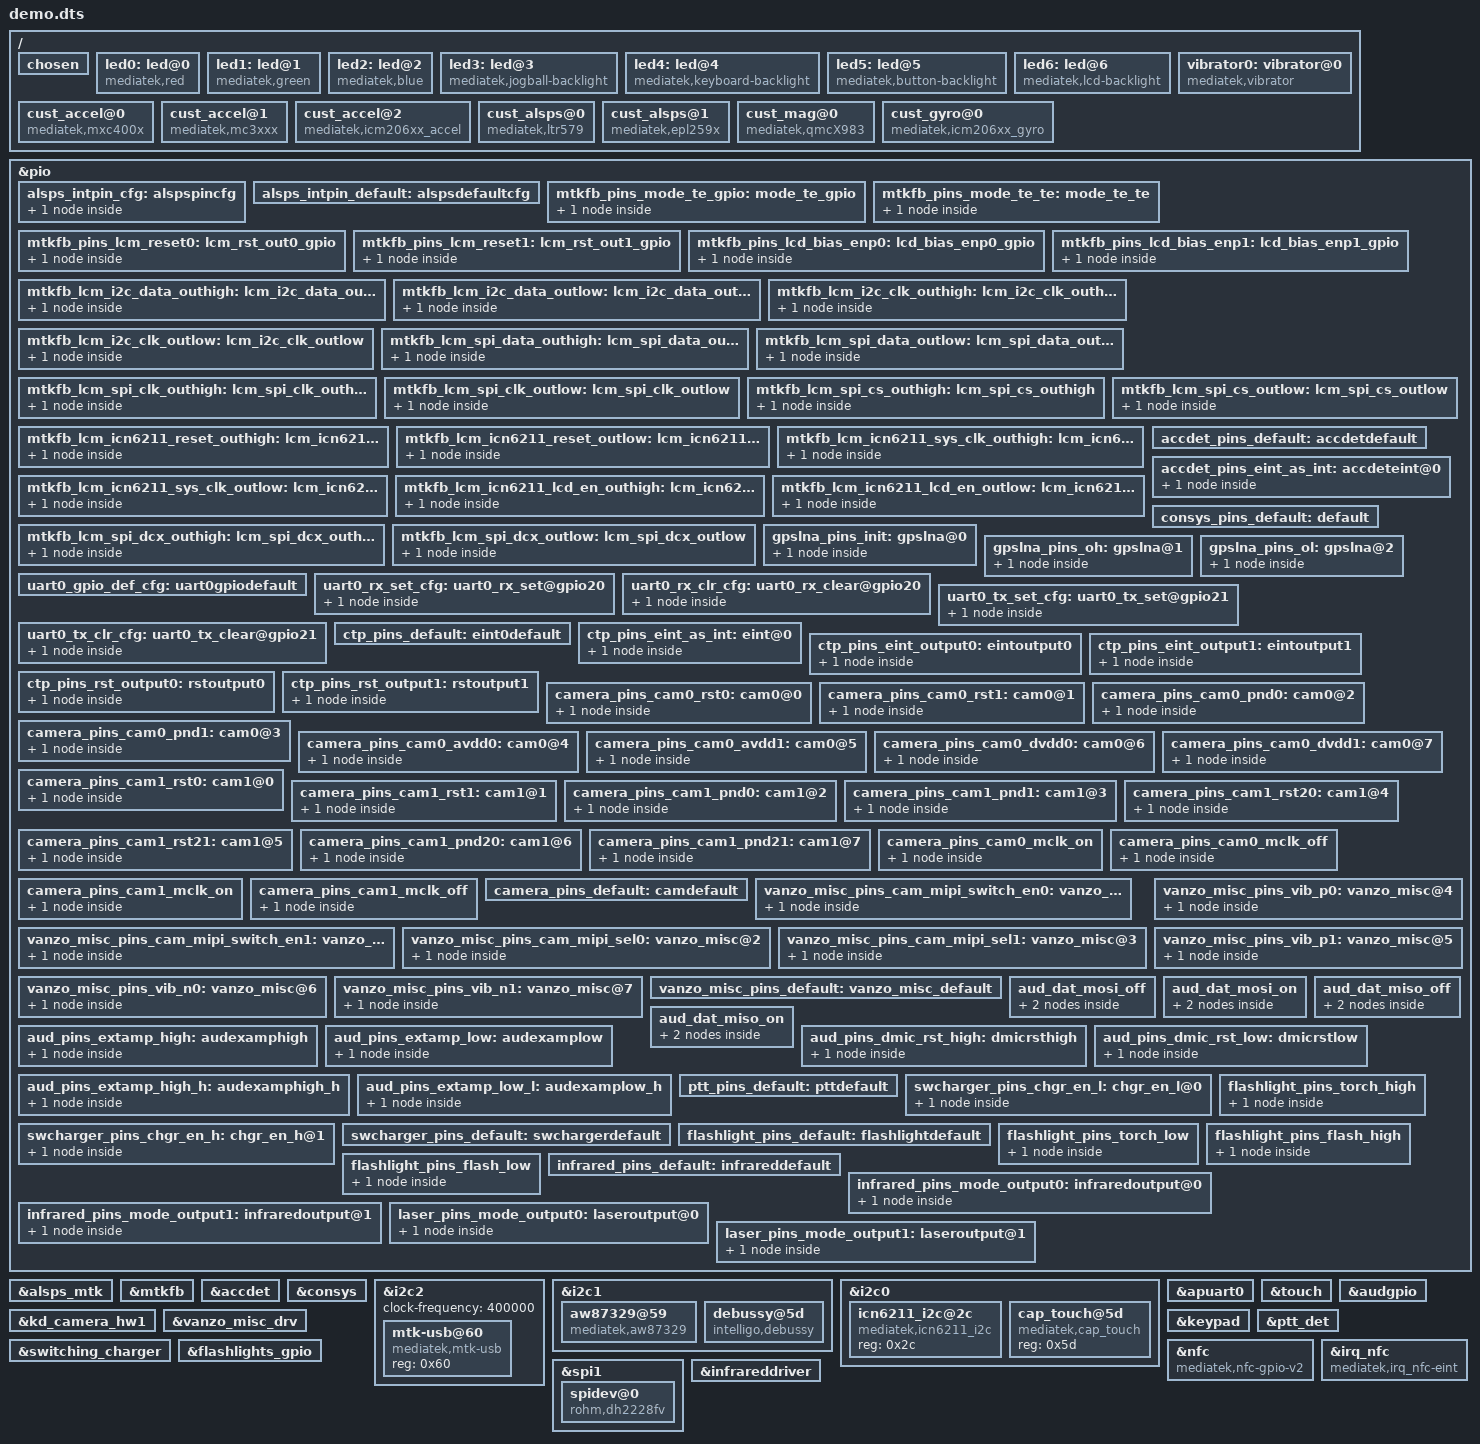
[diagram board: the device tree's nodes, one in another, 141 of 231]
/dts-v1/;
#include "mt6739.dtsi"
#include "cust.dtsi"

/ {
	chosen {
		bootargs = "console=tty0 console=ttyMT0,921600n1 root=/dev/ram initrd=0x44000000,\
0x1000000 loglevel=8 androidboot.selinux=permissive androidboot.hardware=mt6739 initcall_debug=1";
		/* fpga may has no lk, we need to specify display info here */
		/* fb buffer is reserved using this dts by memory node above */

		atag,videolfb-fb_base_l = <0x5e605000>;
		atag,videolfb-fb_base_h = <0>;
		atag,videolfb-islcmfound = <1>;
		atag,videolfb-islcm_inited = <0>;
		atag,videolfb-fps= <6000>;
		atag,videolfb-vramSize= <0x017bb000>;
		atag,videolfb-lcmname= "nt35521_hd_dsi_vdo_truly_nt50358_drv";
	};

	led0:led@0 {
		compatible = "mediatek,red";
		led_mode = <0>;
		data = <1>;
		pwm_config = <0 0 0 0 0>;
	};
	led1:led@1 {
		compatible = "mediatek,green";
		led_mode = <0>;
		data = <1>;
		pwm_config = <0 0 0 0 0>;
	};
	led2:led@2 {
		compatible = "mediatek,blue";
		led_mode = <0>;
		data = <1>;
		pwm_config = <0 0 0 0 0>;
	};
	led3:led@3 {
		compatible = "mediatek,jogball-backlight";
		led_mode = <0>;
		data = <1>;
		pwm_config = <0 0 0 0 0>;
	};
	led4:led@4 {
		compatible = "mediatek,keyboard-backlight";
		led_mode = <0>;
		data = <1>;
		pwm_config = <0 0 0 0 0>;
	};
	led5:led@5 {
		compatible = "mediatek,button-backlight";
		led_mode = <0>;
		data = <1>;
		pwm_config = <0 0 0 0 0>;
	};
	led6:led@6 {
		compatible = "mediatek,lcd-backlight";
		led_mode = <5>;
		data = <1>;
		pwm_config = <0 2 0 0 0>;
	};
	vibrator0:vibrator@0 {
		compatible = "mediatek,vibrator";
		vib_timer = <25>;
		vib_limit = <9>;
		vib_vol= <9>;
	};

/*  start sensor */
	cust_accel@0 {
		compatible = "mediatek,mxc400x";
		i2c_num	= <1>;
		i2c_addr = <0x15 0 0 0>;
		direction = <4>;
		power_id = <0xffff>;
		power_vol = <0>;
		firlen = <0>;
		is_batch_supported = <0>;
	};
	cust_accel@1 {
        compatible = "mediatek,mc3xxx";
        i2c_num = <1>;
        i2c_addr = <0x4c 0 0 0>;
        direction = <4>;
        power_id = <0xffff>;
        power_vol = <0>;
        firlen = <0>;
        is_batch_supported = <0>;
        };
	    cust_accel@2 {
        compatible = "mediatek,icm206xx_accel";
        i2c_num = <1>;
        i2c_addr = <0x68 0 0 0>;
        direction = <4>;
        power_id = <0xffff>;
        power_vol = <0>;
        firlen = <0>;
        is_batch_supported = <0>;
    };
	

	cust_alsps@0 {
        compatible = "mediatek,ltr579";
        i2c_num = <1>;
        i2c_addr = <0x53 0 0 0>;
        polling_mode_ps = <0>;
        polling_mode_als = <1>;
        power_id = <0xffff>;
        power_vol = <0>;
        als_level = <2 20 78 240 320 530 900 1200 1400 1700 2000 2500 3000 12694 35535>;
        als_value = <0 133 304 502 1004 2005 3058 5005 8008 10010 12000 16000 20000 20000 20000 20000>;
        ps_threshold_high = <200>;
        ps_threshold_low = <100>;
        is_batch_supported_ps = <0>;
        is_batch_supported_als = <0>;
    };
        cust_alsps@1 {
        compatible              = "mediatek,epl259x";
        i2c_num             = <2>;
        i2c_addr                = <0x49 0 0 0>;
        polling_mode_ps         = <0>;
        polling_mode_als        = <1>;
        power_id                = <0xffff>;
        power_vol               = <0>;
        als_level = <0 328 861 1377 3125 7721 7767 12621 23062 28430 33274 47116 57694 57694 65535>;
        als_value = <0 133 304 502 1004 2005 3058 5005 8008 10010 12000 16000 20000 20000 20000 20000>;
        ps_threshold_high       =  <34>;
        ps_threshold_low        =  <28>;
        is_batch_supported_ps   = <0>;
        is_batch_supported_als  = <0>;
        };
	
	cust_mag@0 {
        compatible              = "mediatek,qmcX983";
        i2c_num                 = <1>;
        i2c_addr                = <0x2c 0 0 0>;
        direction               = <7>;
        power_id                = <0xffff>;
        power_vol               = <0>;
        is_batch_supported      = <0>;
    };

    cust_gyro@0 {
        compatible          = "mediatek,icm206xx_gyro";
        i2c_num             = <1>;
        i2c_addr            = <0x69 0 0 0>;
        direction           = <4>;
        power_id            = <0xffff>;
        power_vol           = <0>;
        firlen              = <0>;
        is_batch_supported  = <0>;
    };
/* end sensor */
};

/* sensor gpio standization */
&pio {
	alsps_intpin_cfg: alspspincfg {

		pins_cmd_dat {
			pins = <PINMUX_GPIO1__FUNC_GPIO1>;
			slew-rate = <0>;
			bias-pull-up = <MTK_PUPD_SET_R1R0_01>;
		};
	};

	alsps_intpin_default: alspsdefaultcfg {

	};
};

&alsps_mtk {
	pinctrl-names = "pin_default", "pin_cfg";
	pinctrl-0 = <&alsps_intpin_default>;
	pinctrl-1 = <&alsps_intpin_cfg>;
	status = "okay";
};
/* sensor end */

/* DISPSYS GPIO standardization */
&pio {
	mtkfb_pins_mode_te_gpio: mode_te_gpio {
		pins_cmd_dat {
			pins = <PINMUX_GPIO84__FUNC_DSI_TE>;
		};
	};

	mtkfb_pins_mode_te_te: mode_te_te {
		pins_cmd_dat {
			pins = <PINMUX_GPIO84__FUNC_DSI_TE>;
		};
	};

	mtkfb_pins_lcm_reset0: lcm_rst_out0_gpio {
		pins_cmd_dat {
			pins = <PINMUX_GPIO83__FUNC_GPIO83>;
			slew-rate = <1>;
			output-low;
		};
	};

	mtkfb_pins_lcm_reset1: lcm_rst_out1_gpio {
		pins_cmd_dat {
			pins = <PINMUX_GPIO83__FUNC_GPIO83>;
			slew-rate = <1>;
			output-high;
		};
	};

	mtkfb_pins_lcd_bias_enp0: lcd_bias_enp0_gpio {
		pins_cmd_dat {
			pins = <PINMUX_GPIO26__FUNC_GPIO26>;
			slew-rate = <1>;
			output-low;
		};
	};
	mtkfb_pins_lcd_bias_enp1: lcd_bias_enp1_gpio {
		pins_cmd_dat {
			pins = <PINMUX_GPIO26__FUNC_GPIO26>;
			slew-rate = <1>;
			output-high;
		};
	};
	mtkfb_lcm_i2c_data_outhigh: lcm_i2c_data_outhigh {
		pins_cmd_dat {
			pins = <PINMUX_GPIO128__FUNC_GPIO128>;
			slew-rate = <1>;
			output-high;
		};
	};
	mtkfb_lcm_i2c_data_outlow: lcm_i2c_data_outlow {
		pins_cmd_dat {
			pins = <PINMUX_GPIO128__FUNC_GPIO128>;
			slew-rate = <1>;
			output-low;
		};
	};
	mtkfb_lcm_i2c_clk_outhigh: lcm_i2c_clk_outhigh {
		pins_cmd_dat {
			pins = <PINMUX_GPIO129__FUNC_GPIO129>;
			slew-rate = <1>;
			output-high;
		};
	};
	mtkfb_lcm_i2c_clk_outlow: lcm_i2c_clk_outlow {
		pins_cmd_dat {
			pins = <PINMUX_GPIO129__FUNC_GPIO129>;
			slew-rate = <1>;
			output-low;
		};
	};
	mtkfb_lcm_spi_data_outhigh: lcm_spi_data_outhigh {
		pins_cmd_dat {
			pins = <PINMUX_GPIO29__FUNC_GPIO29>;
			slew-rate = <1>;
			output-high;
		};
	};
	mtkfb_lcm_spi_data_outlow: lcm_spi_data_outlow {
		pins_cmd_dat {
			pins = <PINMUX_GPIO29__FUNC_GPIO29>;
			slew-rate = <1>;
			output-low;
		};
	};
	mtkfb_lcm_spi_clk_outhigh: lcm_spi_clk_outhigh {
		pins_cmd_dat {
			pins = <PINMUX_GPIO28__FUNC_GPIO28>;
			slew-rate = <1>;
			output-high;
		};
	};
	mtkfb_lcm_spi_clk_outlow: lcm_spi_clk_outlow {
		pins_cmd_dat {
			pins = <PINMUX_GPIO28__FUNC_GPIO28>;
			slew-rate = <1>;
			output-low;
		};
	};
	mtkfb_lcm_spi_cs_outhigh: lcm_spi_cs_outhigh {
		pins_cmd_dat {
			pins = <PINMUX_GPIO30__FUNC_GPIO30>;
			slew-rate = <1>;
			output-high;
		};
	};
	mtkfb_lcm_spi_cs_outlow: lcm_spi_cs_outlow {
		pins_cmd_dat {
			pins = <PINMUX_GPIO30__FUNC_GPIO30>;
			slew-rate = <1>;
			output-low;
		};
	};

	mtkfb_lcm_icn6211_reset_outhigh: lcm_icn6211_reset_outhigh {
		pins_cmd_dat {
			pins = <PINMUX_GPIO108__FUNC_GPIO108>;
			slew-rate = <1>;
			output-high;
		};
	};
	mtkfb_lcm_icn6211_reset_outlow: lcm_icn6211_reset_outlow {
		pins_cmd_dat {
			pins = <PINMUX_GPIO108__FUNC_GPIO108>;
			slew-rate = <1>;
			output-low;
		};
	};

	mtkfb_lcm_icn6211_sys_clk_outhigh: lcm_icn6211_sys_clk_outhigh {
		pins_cmd_dat {
			pins = <PINMUX_GPIO86__FUNC_GPIO86>;
			slew-rate = <1>;
			output-high;
		};
	};
	mtkfb_lcm_icn6211_sys_clk_outlow: lcm_icn6211_sys_clk_outlow {
		pins_cmd_dat {
			pins = <PINMUX_GPIO86__FUNC_GPIO86>;
			slew-rate = <1>;
			output-low;
		};
	};

	mtkfb_lcm_icn6211_lcd_en_outhigh: lcm_icn6211_lcd_en_outhigh {
		pins_cmd_dat {
			pins = <PINMUX_GPIO109__FUNC_GPIO109>;
			slew-rate = <1>;
			output-high;
		};
	};
	mtkfb_lcm_icn6211_lcd_en_outlow: lcm_icn6211_lcd_en_outlow {
		pins_cmd_dat {
			pins = <PINMUX_GPIO109__FUNC_GPIO109>;
			slew-rate = <1>;
			output-low;
		};
	};
       mtkfb_lcm_spi_dcx_outhigh: lcm_spi_dcx_outhigh {
                               pins_cmd_dat {
                                   pins = <PINMUX_GPIO26__FUNC_GPIO26>;
                                   slew-rate = <1>;
                                   output-high;
                               };
                           };
       mtkfb_lcm_spi_dcx_outlow: lcm_spi_dcx_outlow {
                              pins_cmd_dat {
                                  pins = <PINMUX_GPIO26__FUNC_GPIO26>;
                                  slew-rate = <1>;
                                  output-low;
                              };
                          };

};

&mtkfb {
	pinctrl-names = "mode_te_gpio", "mode_te_te", "lcm_rst_out0_gpio",
		"lcm_rst_out1_gpio", "lcd_bias_enp0_gpio", "lcd_bias_enp1_gpio",
		"lcm_i2c_data_outhigh", "lcm_i2c_data_outlow", "lcm_i2c_clk_outhigh","lcm_i2c_clk_outlow",
		"lcm_spi_data_outhigh", "lcm_spi_data_outlow", "lcm_spi_clk_outhigh","lcm_spi_clk_outlow","lcm_spi_cs_outhigh","lcm_spi_cs_outlow",
		"lcm_icn6211_reset_outhigh","lcm_icn6211_reset_outlow","lcm_icn6211_sys_clk_outhigh","lcm_icn6211_sys_clk_outlow","lcm_icn6211_lcd_en_outhigh","lcm_icn6211_lcd_en_outlow","lcm_spi_dcx_outhigh","lcm_spi_dcx_outlow";
	pinctrl-0 = <&mtkfb_pins_mode_te_gpio>;
	pinctrl-1 = <&mtkfb_pins_mode_te_te>;
	pinctrl-2 = <&mtkfb_pins_lcm_reset0>;
	pinctrl-3 = <&mtkfb_pins_lcm_reset1>;
	pinctrl-4 = <&mtkfb_pins_lcd_bias_enp0>;
	pinctrl-5 = <&mtkfb_pins_lcd_bias_enp1>;
	pinctrl-6 = <&mtkfb_lcm_i2c_data_outhigh>;
	pinctrl-7 = <&mtkfb_lcm_i2c_data_outlow>;
	pinctrl-8 = <&mtkfb_lcm_i2c_clk_outhigh>;
	pinctrl-9 = <&mtkfb_lcm_i2c_clk_outlow>;
	pinctrl-10 = <&mtkfb_lcm_spi_data_outhigh>;
	pinctrl-11 = <&mtkfb_lcm_spi_data_outlow>;
	pinctrl-12 = <&mtkfb_lcm_spi_clk_outhigh>;
	pinctrl-13 = <&mtkfb_lcm_spi_clk_outlow>;
	pinctrl-14 = <&mtkfb_lcm_spi_cs_outhigh>;
	pinctrl-15 = <&mtkfb_lcm_spi_cs_outlow>;
	pinctrl-16 = <&mtkfb_lcm_icn6211_reset_outhigh>;
	pinctrl-17 = <&mtkfb_lcm_icn6211_reset_outlow>;
	pinctrl-18 = <&mtkfb_lcm_icn6211_sys_clk_outhigh>;
	pinctrl-19 = <&mtkfb_lcm_icn6211_sys_clk_outlow>;
	pinctrl-20 = <&mtkfb_lcm_icn6211_lcd_en_outhigh>;
	pinctrl-21 = <&mtkfb_lcm_icn6211_lcd_en_outlow>;
        pinctrl-22 = <&mtkfb_lcm_spi_dcx_outhigh>;
        pinctrl-23 = <&mtkfb_lcm_spi_dcx_outlow>;
	status = "okay";
};
/* DISPSYS GPIO standardization end */


/* accdet start */
&accdet {
	/* accdet micbias voltage: 0x07,2.7v;0x05,2.5v;0x02,1.9v */
	accdet-mic-vol = <6>;
	headset-mode-setting = <0x500 0x500 1 0x1f0 0x800 0x800 0x20 0x44>;
	accdet-plugout-debounce = <1>;
	/*1:ACC mode, 2:low cost without in bias, 6:low cost with in bias*/
	accdet-mic-mode = <1>;
	/* eint_level_trigger: 8,LEVEL_LOW(default);4,LEVEL_HIGH;others,LEVEL_LOW */
	headset-eint-level-pol = <8>;
	/*0--MD_MAX--UP_MAX--DW_MAX*/
	headset-three-key-threshold = <0 80 220 400>;
	headset-three-key-threshold-CDD = <0 121 192 600>;
	/*0--MD_MAX--VOICE_MAX--UP_MAX--DW_MAX*/
	headset-four-key-threshold = <0 58 121 192 400>;
	/* ACCDET GPIO standardization ACC mode no use */
	pinctrl-names = "default", "state_eint_as_int";
	pinctrl-0 = <&accdet_pins_default>;
	pinctrl-1 = <&accdet_pins_eint_as_int>;
	status = "okay";
};
&pio {
	accdet_pins_default: accdetdefault {
	};
	accdet_pins_eint_as_int: accdeteint@0 {
		pins_cmd_dat {
			/*pins = <PINMUX_GPIO51__FUNC_GPIO51>;*/
			slew-rate = <0>;
			bias-disable;
		};
	};
};
/* accdet end */

/* CONSYS GPIO standardization */
&pio {
	consys_pins_default: default {
	};
	gpslna_pins_init: gpslna@0 {
		pins_cmd_dat {
			pins = <PINMUX_GPIO125__FUNC_GPIO125>;
			slew-rate = <0>;
			bias-disable;
			output-low;
		};
	};
	gpslna_pins_oh: gpslna@1 {
		pins_cmd_dat {
			pins = <PINMUX_GPIO125__FUNC_GPIO125>;
			slew-rate = <1>;
			output-high;
		};
	};
	gpslna_pins_ol: gpslna@2 {
		pins_cmd_dat {
			pins = <PINMUX_GPIO125__FUNC_GPIO125>;
			slew-rate = <1>;
			output-low;
		};
	};
};
&consys {
	pinctrl-names = "default", "gps_lna_state_init", "gps_lna_state_oh", "gps_lna_state_ol";
	pinctrl-0 = <&consys_pins_default>;
	pinctrl-1 = <&gpslna_pins_init>;
	pinctrl-2 = <&gpslna_pins_oh>;
	pinctrl-3 = <&gpslna_pins_ol>;
	status = "okay";
};

&i2c2 {
	#address-cells = <1>;
	#size-cells = <0>;
	clock-frequency = <400000>;

	mtk-usb@60 {
		compatible = "mediatek,mtk-usb";
		reg = <0x60>;
		status = "okay";
	};
};

&i2c1 {
#address-cells = <1>;
#size-cells = <0>;
    clock-frequency = <400000>;
    mediatek,use-open-drain;

    aw87329@59 {
        compatible = "mediatek,aw87329";
        reg = <0x59>;
        reset-gpio = <&pio 123 0>;
        status = "okay";
    };

    debussy@5d{
        status = "okay";
        compatible = "intelligo,debussy";
        reg = <0x5d>;
        ig,reset-gpio = <&pio 15 0>;
        ig,reset-hold-time = <5>;
        ig,reset-release-time = <150>;
        ig,enable-kws = <1>;
        ig,debounce = <2>;
        ig,device_name = "debussy.5d";
        ig,max_data_length_i2c = <256>;
        ig,enable-spi = <0>;
    };
};


&i2c0 {
#address-cells = <1>;
#size-cells = <0>;
    clock-frequency = <400000>;
    mediatek,use-open-drain;
    icn6211_i2c@2c {
        compatible = "mediatek,icn6211_i2c";
        reg = <0x2c>;
        status = "okay";
    };

    cap_touch@5d {
        compatible = "mediatek,cap_touch";
        reg = <0x5d>;
        status = "okay";
    };

};

/* UART GPIO */
&apuart0 {
	pinctrl-names = "uart0_gpio_default",
			"uart0_rx_set",
			"uart0_rx_clear",
			"uart0_tx_set",
			"uart0_tx_clear";
	pinctrl-0 = <&uart0_gpio_def_cfg>;
	pinctrl-1 = <&uart0_rx_set_cfg>;
	pinctrl-2 = <&uart0_rx_clr_cfg>;
	pinctrl-3 = <&uart0_tx_set_cfg>;
	pinctrl-4 = <&uart0_tx_clr_cfg>;
	status = "okay";
};

&pio {
	/* UART GPIO Settings - Start */
	/* UART0: rx set, rx clear, tx clear, tx clear*/
	uart0_gpio_def_cfg:uart0gpiodefault {

	};
	uart0_rx_set_cfg:uart0_rx_set@gpio20 {
		pins_cmd_dat {
			pins = <PINMUX_GPIO20__FUNC_UART0RX>;
		};
	};
	uart0_rx_clr_cfg:uart0_rx_clear@gpio20 {
		pins_cmd_dat {
			pins = <PINMUX_GPIO20__FUNC_GPIO20>;
			slew-rate = <1>;
			output-high;
		};
	};
	uart0_tx_set_cfg:uart0_tx_set@gpio21 {
		pins_cmd_dat {
			pins = <PINMUX_GPIO21__FUNC_UART0TX>;
		};
	};
	uart0_tx_clr_cfg:uart0_tx_clear@gpio21 {
		pins_cmd_dat {
			pins = <PINMUX_GPIO21__FUNC_GPIO21>;
			slew-rate = <1>;
			output-high;
		};
	};
};/* UART GPIO end */

/* TOUCH start */
&touch {
	tpd-resolution = <720 1280>;
	use-tpd-button = <0>;
	tpd-key-num = <3>;
	tpd-key-local= <139 172 158 0>;
	tpd-key-dim-local = <90 883 100 40 230 883 100 40 370 883 100 40 0 0 0 0>;
	tpd-max-touch-num = <5>;
	tpd-filter-enable = <1>;
	tpd-filter-pixel-density = <106>;
	tpd-filter-custom-prameters = <0 0 0 0 0 0 0 0 0 0 0 0>;
	tpd-filter-custom-speed = <0 0 0>;
	pinctrl-names = "default", "state_eint_as_int", "state_eint_output0", "state_eint_output1",
		"state_rst_output0", "state_rst_output1";
	pinctrl-0 = <&ctp_pins_default>;
	pinctrl-1 = <&ctp_pins_eint_as_int>;
	pinctrl-2 = <&ctp_pins_eint_output0>;
	pinctrl-3 = <&ctp_pins_eint_output1>;
	pinctrl-4 = <&ctp_pins_rst_output0>;
	pinctrl-5 = <&ctp_pins_rst_output1>;
	status = "okay";
};
&pio {
	ctp_pins_default: eint0default {
	};
	ctp_pins_eint_as_int: eint@0 {
		pins_cmd_dat {
			pins = <PINMUX_GPIO6__FUNC_GPIO6>;
			slew-rate = <0>;
			bias-disable;
		};
	};
	ctp_pins_eint_output0: eintoutput0 {
		pins_cmd_dat {
			pins = <PINMUX_GPIO6__FUNC_GPIO6>;
			slew-rate = <1>;
			output-low;
		};
	};
	ctp_pins_eint_output1: eintoutput1 {
		pins_cmd_dat {
			pins = <PINMUX_GPIO6__FUNC_GPIO6>;
			slew-rate = <1>;
			output-high;
		};
	};
	ctp_pins_rst_output0: rstoutput0 {
		pins_cmd_dat {
			pins = <PINMUX_GPIO124__FUNC_GPIO124>;
			slew-rate = <1>;
			output-low;
		};
	};
	ctp_pins_rst_output1: rstoutput1 {
		pins_cmd_dat {
			pins = <PINMUX_GPIO124__FUNC_GPIO124>;
			slew-rate = <1>;
			output-high;
		};
	};
};
/* TOUCH end */

/* CAMERA GPIO standardization */
&pio {
camera_pins_cam0_rst0: cam0@0 {
                           pins_cmd_dat {
                               pins = <PINMUX_GPIO33__FUNC_GPIO33>;
                               slew-rate = <1>; /*direction 0:in, 1:out*/
                               output-low;/*direction out used only. output_low or high*/
                           };
                       };
camera_pins_cam0_rst1: cam0@1 {
                           pins_cmd_dat {
                               pins = <PINMUX_GPIO33__FUNC_GPIO33>;
                               slew-rate = <1>;
                               output-high;
                           };
                       };
camera_pins_cam0_pnd0: cam0@2 {
                           pins_cmd_dat {
                               pins = <PINMUX_GPIO34__FUNC_GPIO34>;
                               slew-rate = <1>;
                               output-low;
                           };
                       };
camera_pins_cam0_pnd1: cam0@3 {
                           pins_cmd_dat {
                               pins = <PINMUX_GPIO34__FUNC_GPIO34>;
                               slew-rate = <1>;
                               output-high;
                           };
                       };
camera_pins_cam0_avdd0: cam0@4 {
                           pins_cmd_dat {
                               pins = <PINMUX_GPIO36__FUNC_GPIO36>;
                               slew-rate = <1>;
                               output-low;
                           };
                       };
camera_pins_cam0_avdd1: cam0@5 {
                           pins_cmd_dat {
                               pins = <PINMUX_GPIO36__FUNC_GPIO36>;
                               slew-rate = <1>;
                               output-high;
                           };
                       };
camera_pins_cam0_dvdd0: cam0@6 {
                           pins_cmd_dat {
                               pins = <PINMUX_GPIO9__FUNC_GPIO9>;
                               slew-rate = <1>;
                               output-low;
                           };
                       };
camera_pins_cam0_dvdd1: cam0@7 {
                           pins_cmd_dat {
                               pins = <PINMUX_GPIO9__FUNC_GPIO9>;
                               slew-rate = <1>;
                               output-high;
                           };
                       };
camera_pins_cam1_rst0: cam1@0 {
                           pins_cmd_dat {
                               pins = <PINMUX_GPIO22__FUNC_GPIO22>;
                               slew-rate = <1>; /*direction 0:in, 1:out*/
                               output-low;/*direction out used only. output_low or high*/
                           };
                       };
camera_pins_cam1_rst1: cam1@1 {
                           pins_cmd_dat {
                               pins = <PINMUX_GPIO22__FUNC_GPIO22>;
                               slew-rate = <1>;
                               output-high;
                           };
                       };
camera_pins_cam1_pnd0: cam1@2 {
                           pins_cmd_dat {
                               pins = <PINMUX_GPIO23__FUNC_GPIO23>;
                               slew-rate = <1>;
                               output-low;
                           };
                       };
camera_pins_cam1_pnd1: cam1@3 {
                           pins_cmd_dat {
                               pins = <PINMUX_GPIO23__FUNC_GPIO23>;
                               slew-rate = <1>;
                               output-high;
                           };
                       };
camera_pins_cam1_rst20: cam1@4 {
                           pins_cmd_dat {
                               pins = <PINMUX_GPIO32__FUNC_GPIO32>;
                               slew-rate = <1>; /*direction 0:in, 1:out*/
                               output-low;/*direction out used only. output_low or high*/
                           };
                       };
camera_pins_cam1_rst21: cam1@5 {
                           pins_cmd_dat {
                               pins = <PINMUX_GPIO32__FUNC_GPIO32>;
                               slew-rate = <1>;
                               output-high;
                           };
                       };
camera_pins_cam1_pnd20: cam1@6 {
                           pins_cmd_dat {
                               pins = <PINMUX_GPIO31__FUNC_GPIO31>;
                               slew-rate = <1>;
                               output-low;
                           };
                       };
camera_pins_cam1_pnd21: cam1@7 {
                           pins_cmd_dat {
                               pins = <PINMUX_GPIO31__FUNC_GPIO31>;
                               slew-rate = <1>;
                               output-high;
                           };
                       };
camera_pins_cam0_mclk_on: camera_pins_cam0_mclk_on {
                              pins_cmd_dat {
                                  pins = <PINMUX_GPIO126__FUNC_CMMCLK0>;
                              };
                          };
camera_pins_cam0_mclk_off: camera_pins_cam0_mclk_off {
                               pins_cmd_dat {
                                   pins = <PINMUX_GPIO126__FUNC_GPIO126>;
                               };
                           };
camera_pins_cam1_mclk_on: camera_pins_cam1_mclk_on {
                              pins_cmd_dat {
                                  pins = <PINMUX_GPIO126__FUNC_CMMCLK0>;
                              };
                          };
camera_pins_cam1_mclk_off: camera_pins_cam1_mclk_off {
                               pins_cmd_dat {
                                   pins = <PINMUX_GPIO126__FUNC_GPIO126>;
                               };
                           };
camera_pins_default: camdefault {
                     };

};

&kd_camera_hw1 {
    pinctrl-names = "default",
        "cam0_rst0", "cam0_rst1", "cam0_pnd0", "cam0_pnd1","cam_ldo_vcama_0","cam_ldo_vcama_1",
        "cam1_rst0", "cam1_rst1", "cam1_pnd0", "cam1_pnd1",
        "cam0_mclk_on", "cam0_mclk_off",
        "cam1_mclk_on", "cam1_mclk_off",
        "cam1_rst20","cam1_rst21","cam1_pnd20","cam1_pnd21","cam_ldo_vcamd_1","cam_ldo_vcamd_0";

    pinctrl-0 = <&camera_pins_default>;
    pinctrl-1 = <&camera_pins_cam0_rst0>;
    pinctrl-2 = <&camera_pins_cam0_rst1>;
    pinctrl-3 = <&camera_pins_cam0_pnd0>;
    pinctrl-4 = <&camera_pins_cam0_pnd1>;
    pinctrl-5 = <&camera_pins_cam0_avdd0>;
    pinctrl-6 = <&camera_pins_cam0_avdd1>;
    pinctrl-7 = <&camera_pins_cam1_rst0>;
    pinctrl-8 = <&camera_pins_cam1_rst1>;
    pinctrl-9 = <&camera_pins_cam1_pnd0>;
    pinctrl-10 = <&camera_pins_cam1_pnd1>;
    pinctrl-11 = <&camera_pins_cam0_mclk_on>;
    pinctrl-12 = <&camera_pins_cam0_mclk_off>;
    pinctrl-13 = <&camera_pins_cam1_mclk_on>;
    pinctrl-14 = <&camera_pins_cam1_mclk_off>;
    pinctrl-15 = <&camera_pins_cam1_rst20>;
    pinctrl-16 = <&camera_pins_cam1_rst21>;
    pinctrl-17 = <&camera_pins_cam1_pnd20>;
    pinctrl-18 = <&camera_pins_cam1_pnd21>;
    pinctrl-19 = <&camera_pins_cam0_dvdd1>;
    pinctrl-20 = <&camera_pins_cam0_dvdd0>;
    status = "okay";

};

/* CAMERA GPIO end */

&pio {
vanzo_misc_pins_cam_mipi_switch_en0: vanzo_misc@0 {
                           pins_cmd_dat {
                               pins = <PINMUX_GPIO53__FUNC_GPIO53>;
                               slew-rate = <1>;
                               output-low;
                           };
                       };
vanzo_misc_pins_cam_mipi_switch_en1: vanzo_misc@1 {
                           pins_cmd_dat {
                               pins = <PINMUX_GPIO53__FUNC_GPIO53>;
                               slew-rate = <1>;
                               output-high;
                           };
                       };
vanzo_misc_pins_cam_mipi_sel0: vanzo_misc@2 {
                           pins_cmd_dat {
                               pins = <PINMUX_GPIO54__FUNC_GPIO54>;
                               slew-rate = <1>;
                               output-low;
                           };
                       };
vanzo_misc_pins_cam_mipi_sel1: vanzo_misc@3 {
                           pins_cmd_dat {
                               pins = <PINMUX_GPIO54__FUNC_GPIO54>;
                               slew-rate = <1>;
                               output-high;
                           };
                       };
vanzo_misc_pins_vib_p0: vanzo_misc@4 {
                           pins_cmd_dat {
                               pins = <PINMUX_GPIO2__FUNC_GPIO2>;
                               slew-rate = <1>;
                               output-low;
                           };
                       };
vanzo_misc_pins_vib_p1: vanzo_misc@5 {
                           pins_cmd_dat {
                               pins = <PINMUX_GPIO2__FUNC_GPIO2>;
                               slew-rate = <1>;
                               output-high;
                           };
                       };
vanzo_misc_pins_vib_n0: vanzo_misc@6 {
                           pins_cmd_dat {
                               pins = <PINMUX_GPIO3__FUNC_GPIO3>;
                               slew-rate = <1>;
                               output-low;
                           };
                       };
vanzo_misc_pins_vib_n1: vanzo_misc@7 {
                           pins_cmd_dat {
                               pins = <PINMUX_GPIO3__FUNC_GPIO3>;
                               slew-rate = <1>;
                               output-high;
                           };
                       };
vanzo_misc_pins_default: vanzo_misc_default {
                         };
};
&vanzo_misc_drv {
    pinctrl-names = "default","cam_mipi_switch_en_1","cam_mipi_switch_en_0","cam_mipi_switch_sel_1","cam_mipi_switch_sel_0","vib_p1","vib_p0","vib_n1","vib_n0";
    pinctrl-0 = <&vanzo_misc_pins_default>;
    pinctrl-1 = <&vanzo_misc_pins_cam_mipi_switch_en1>;
    pinctrl-2 = <&vanzo_misc_pins_cam_mipi_switch_en0>;
    pinctrl-3 = <&vanzo_misc_pins_cam_mipi_sel1>;
    pinctrl-4 = <&vanzo_misc_pins_cam_mipi_sel0>;
    pinctrl-5 = <&vanzo_misc_pins_vib_p1>;
    pinctrl-6 = <&vanzo_misc_pins_vib_p0>;
    pinctrl-7 = <&vanzo_misc_pins_vib_n1>;
    pinctrl-8 = <&vanzo_misc_pins_vib_n0>;
};
/* AUDIO GPIO standardization */
&audgpio {
	pinctrl-names = "aud_dat_mosi_off",
			"aud_dat_mosi_on",
			"aud_dat_miso_off",
			"aud_dat_miso_on",
			"extamp-pullhigh",
			"extamp-pulllow",
			"dmic_rst_high",
			"dmic_rst_low";
	pinctrl-0 = <&aud_dat_mosi_off>;
	pinctrl-1 = <&aud_dat_mosi_on>;
	pinctrl-2 = <&aud_dat_miso_off>;
	pinctrl-3 = <&aud_dat_miso_on>;
	pinctrl-4 = <&aud_pins_extamp_high>;
	pinctrl-5 = <&aud_pins_extamp_low>;
	pinctrl-6 = <&aud_pins_dmic_rst_high>;
	pinctrl-7 = <&aud_pins_dmic_rst_low>;
	status = "okay";
};

&pio {
	aud_dat_mosi_off: aud_dat_mosi_off {
		pins_cmd1_dat {
			pins = <PINMUX_GPIO63__FUNC_GPIO63>;
			input-enable;
			slew-rate = <0>;
			bias-disable;
		};
		pins_cmd2_dat {
			pins = <PINMUX_GPIO64__FUNC_GPIO64>;
			input-enable;
			slew-rate = <0>;
			bias-disable;
		};
	};

	aud_dat_mosi_on: aud_dat_mosi_on {
		pins_cmd1_dat {
			pins = <PINMUX_GPIO63__FUNC_AUD_DAT_MOSI0>;
		};
		pins_cmd2_dat {
			pins = <PINMUX_GPIO64__FUNC_AUD_DAT_MOSI1>;
		};
	};

	aud_dat_miso_off: aud_dat_miso_off {
		pins_cmd1_dat {
			pins = <PINMUX_GPIO67__FUNC_GPIO67>;
			input-enable;
			slew-rate = <0>;
			bias-disable;
		};
		pins_cmd2_dat {
			pins = <PINMUX_GPIO68__FUNC_GPIO68>;
			input-enable;
			slew-rate = <0>;
			bias-disable;
		};
	};

	aud_dat_miso_on: aud_dat_miso_on {
		pins_cmd1_dat {
			pins = <PINMUX_GPIO67__FUNC_AUD_DAT_MISO0>;
		};
		pins_cmd2_dat {
			pins = <PINMUX_GPIO68__FUNC_AUD_DAT_MISO1>;
		};
	};
	aud_pins_extamp_high: audexamphigh {
		pins_cmd_dat {
			pins = <PINMUX_GPIO123__FUNC_GPIO123>;
			slew-rate = <1>;
			output-high;
		};
	};

	aud_pins_extamp_low: audexamplow {
		pins_cmd_dat {
			pins = <PINMUX_GPIO123__FUNC_GPIO123>;
			slew-rate = <1>;
			output-low;
		};
	};
	aud_pins_dmic_rst_high: dmicrsthigh {
		pins_cmd_dat {
			pins = <PINMUX_GPIO15__FUNC_GPIO15>;
			slew-rate = <1>;
			output-high;
		};
	};

	aud_pins_dmic_rst_low: dmicrstlow {
		pins_cmd_dat {
			pins = <PINMUX_GPIO15__FUNC_GPIO15>;
			slew-rate = <1>;
			output-low;
		};
	};

};
/* AUDIO end */
/* intercom */
&pio {
	aud_pins_extamp_high_h: audexamphigh_h {
		pins_cmd_dat {
			pins = <PINMUX_GPIO123__FUNC_GPIO123>;
			slew-rate = <1>;
			output-high;
		};
	};

	aud_pins_extamp_low_l: audexamplow_h {
		pins_cmd_dat {
			pins = <PINMUX_GPIO123__FUNC_GPIO123>;
			slew-rate = <1>;
			output-low;
		};
	};

ptt_pins_default: pttdefault {
};
};

&keypad {
    pinctrl-names = "default","audexamphigh_h","audexamplow_l";
    pinctrl-0 = <&ptt_pins_default>;
    pinctrl-1 = <&aud_pins_extamp_high_h>;
    pinctrl-2 = <&aud_pins_extamp_low_l>;
    status = "okay";

};
/* intercom end */

&ptt_det{
    interrupt-parent = <&pio>;
    interrupts = <12 IRQ_TYPE_EDGE_FALLING 12 0>;
    status = "okay";
};



/* SWCHARGER GPIO standardization */
&pio {
swcharger_pins_chgr_en_l: chgr_en_l@0 {
	pins_cmd_dat {
		pins = <PINMUX_GPIO8__FUNC_GPIO8>;/*GPIO_SWCHARGER_EN_PIN*/
		slew-rate = <1>; /*direction 0:in, 1:out*/
		output-low;/*direction out used only. output_low or high*/
	};
};
swcharger_pins_chgr_en_h: chgr_en_h@1 {
	pins_cmd_dat {
		pins = <PINMUX_GPIO8__FUNC_GPIO8>;/*GPIO_SWCHARGER_EN_PIN*/
		slew-rate = <1>;
		output-high;
	};
};
swcharger_pins_default: swchargerdefault {
};
};

&switching_charger {
    pinctrl-names = "default", "chgr_en_l", "chgr_en_h";
    pinctrl-0 = <&swcharger_pins_default>;
    pinctrl-1 = <&swcharger_pins_chgr_en_l>;
    pinctrl-2 = <&swcharger_pins_chgr_en_h>;
    status = "okay";

};
/* SWCHARGER GPIO end */

/* flash light standardization */
&flashlights_gpio {
    pinctrl-names = "default","torch_high","torch_low","flash_high","flash_low";
    pinctrl-0 = <&flashlight_pins_default>;
    pinctrl-1 = <&flashlight_pins_torch_high>;
    pinctrl-2 = <&flashlight_pins_torch_low>;
    pinctrl-3 = <&flashlight_pins_flash_high>;
    pinctrl-4 = <&flashlight_pins_flash_low>;
    status = "okay";
};

&pio {
    flashlight_pins_default: flashlightdefault {
    };
    flashlight_pins_torch_high: flashlight_pins_torch_high {
        pins_cmd_dat {
            pins = <PINMUX_GPIO14__FUNC_GPIO14>;
            slew-rate = <1>;
            bias-pull-down = <00>;
            output-high;
            input-schmitt-enable = <0>;
        };
    };
    flashlight_pins_torch_low: flashlight_pins_torch_low {
        pins_cmd_dat {
            pins = <PINMUX_GPIO14__FUNC_GPIO14>;
            slew-rate = <1>;
            bias-pull-down = <00>;
            output-low;
            input-schmitt-enable = <0>;
        };
    };
    flashlight_pins_flash_high: flashlight_pins_flash_high {
        pins_cmd_dat {
            pins = <PINMUX_GPIO5__FUNC_GPIO5>;
            slew-rate = <1>;
            output-high;
        };
    };
    flashlight_pins_flash_low: flashlight_pins_flash_low {
        pins_cmd_dat {
            pins = <PINMUX_GPIO5__FUNC_GPIO5>;
            slew-rate = <1>;
            output-low;
        };
    };
};
/*flash gpio end */

/* NFC start */
&nfc {
	compatible = "mediatek,nfc-gpio-v2";
	gpio-rst = <0>;
	gpio-rst-std = <&pio 0 0x0>;
	gpio-irq = <7>;
	gpio-irq-std = <&pio 7 0x0>;
};

&irq_nfc {
	compatible = "mediatek,irq_nfc-eint";
};
/* NFC end */

&spi1{
    #address-cells = <1>;
    #size-cells = <0>;
    spidev@0{
        compatible = "rohm,dh2228fv";
        reg = <0x0>;
        spi-max-frequency = <5000000>;
    };
};

/* INFRARED start*/
&infrareddriver {
    pinctrl-names = "default", "state_infrared_output0", "state_infrared_output1", "state_laser_output0", "state_laser_output1",
						"torch_high","torch_low","flash_high","flash_low";
    pinctrl-0 = <&infrared_pins_default>;
    pinctrl-1 = <&infrared_pins_mode_output0>;
    pinctrl-2 = <&infrared_pins_mode_output1>;
    pinctrl-3 = <&laser_pins_mode_output0>;
    pinctrl-4 = <&laser_pins_mode_output1>;
    pinctrl-5 = <&flashlight_pins_torch_high>;
    pinctrl-6 = <&flashlight_pins_torch_low>;
    pinctrl-7 = <&flashlight_pins_flash_high>;
    pinctrl-8 = <&flashlight_pins_flash_low>;

    status = "okay";
};

&pio {
infrared_pins_default: infrareddefault {
                       };
infrared_pins_mode_output0: infraredoutput@0 {
                                pins_cmd_dat {
                                    pins = <PINMUX_GPIO24__FUNC_GPIO24>;
                                    slew-rate = <1>;
                                    output-low;
                                };
                       };
infrared_pins_mode_output1: infraredoutput@1 {
                                pins_cmd_dat {
                                    pins = <PINMUX_GPIO24__FUNC_GPIO24>;
                                    slew-rate = <1>;
                                    output-high;
                                };
                       };
laser_pins_mode_output0: laseroutput@0 {
                                pins_cmd_dat {
                                    pins = <PINMUX_GPIO4__FUNC_GPIO4>;
                                    slew-rate = <1>;
                                    output-low;
                                };
                       };
laser_pins_mode_output1: laseroutput@1 {
                                pins_cmd_dat {
                                    pins = <PINMUX_GPIO4__FUNC_GPIO4>;
                                    slew-rate = <1>;
                                    output-high;
                                };
                       };
    flashlight_pins_torch_high: flashlight_pins_torch_high {
        pins_cmd_dat {
            pins = <PINMUX_GPIO14__FUNC_GPIO14>;
            slew-rate = <1>;
            bias-pull-down = <00>;
            output-high;
            input-schmitt-enable = <0>;
        };
    };
    flashlight_pins_torch_low: flashlight_pins_torch_low {
        pins_cmd_dat {
            pins = <PINMUX_GPIO14__FUNC_GPIO14>;
            slew-rate = <1>;
            bias-pull-down = <00>;
            output-low;
            input-schmitt-enable = <0>;
        };
    };
    flashlight_pins_flash_high: flashlight_pins_flash_high {
        pins_cmd_dat {
            pins = <PINMUX_GPIO5__FUNC_GPIO5>;
            slew-rate = <1>;
            output-high;
        };
    };
    flashlight_pins_flash_low: flashlight_pins_flash_low {
        pins_cmd_dat {
            pins = <PINMUX_GPIO5__FUNC_GPIO5>;
            slew-rate = <1>;
            output-low;
        };
    };
};
/* INFRARED end*/

